# ESW3120 register map
Vendor: Shanghai Eastsoft Microelectronics Co.,Ltd.; Series: ARMCM3; File version: 1.2
CPU: CM3 r2p1, little endian, MPU, no FPU, 4 interrupt priority bits
Registers are 32-bit, read-write, reset 0x0 unless marked. A register's access mark holds for its fields unless they carry their own. Offsets are from the block's base; [hi:lo] are bit positions; {n}, {i} and the like mark numbered series.

## ADPCM
Base 0x40008800
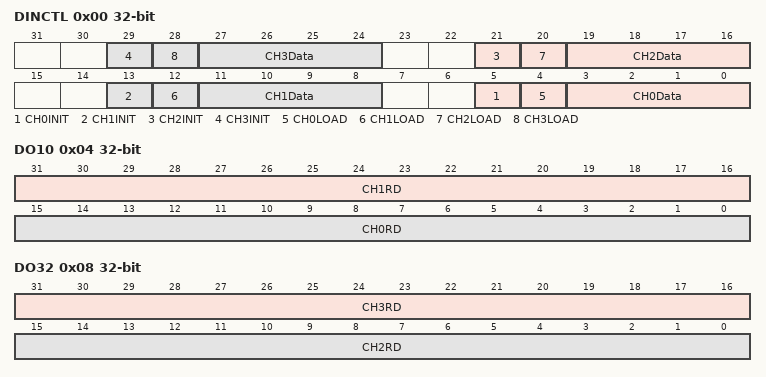
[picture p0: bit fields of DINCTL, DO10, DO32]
0x00 DINCTL
  [8n+5] CH{n}INIT (n=0..3), [8n+4] CH{n}LOAD (n=0..3), [8n+3:8n] CH{n}Data (n=0..3)
0x04 DO10 read
  [31:16] CH1RD, [15:0] CH0RD
0x08 DO32 read
  [31:16] CH3RD, [15:0] CH2RD
0x0C IER trigger-write1
  [0] IER
0x10 IDR trigger-write1
  [0] IDR
0x14 IMR read
  [0] IMR
0x18 RIS read
  [0] RIS
0x1C ISC write1
  [0] ISC read-clear-write1
0x20 STATUS read
  [0] DEC_READY
0x24 DMACTRL
  [0] DECDMAEN

## ADC
Base 0x40042000
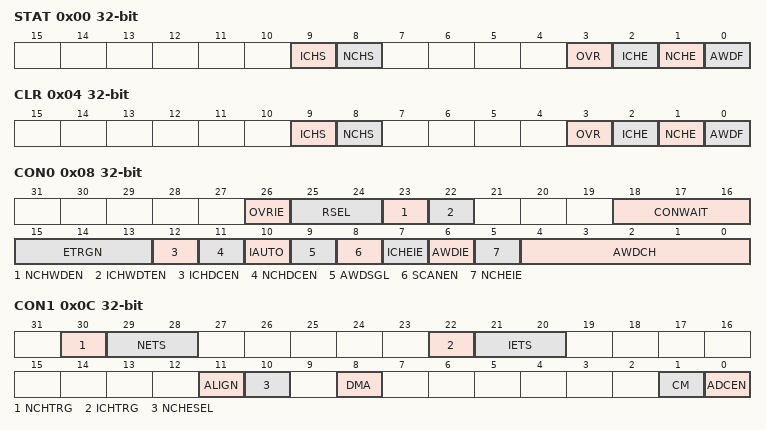
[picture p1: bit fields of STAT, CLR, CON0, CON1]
0x00 STAT read
  [9] ICHS, [8] NCHS, [3] OVR, [2] ICHE, [1] NCHE, [0] AWDF
0x04 CLR write1
  [9] ICHS, [8] NCHS, [3] OVR, [2] ICHE, [1] NCHE, [0] AWDF
0x08 CON0
  [26] OVRIE, [25:24] RSEL, [23] NCHWDEN, [22] ICHWDTEN, [18:16] CONWAIT, [15:13] ETRGN, [12] ICHDCEN, [11] NCHDCEN, [10] IAUTO, [9] AWDSGL, [8] SCANEN, [7] ICHEIE, [6] AWDIE, [5] NCHEIE, [4:0] AWDCH
0x0C CON1
  [30] NCHTRG write1, [29:28] NETS, [22] ICHTRG write1, [21:20] IETS, [11] ALIGN, [10] NCHESEL, [8] DMA, [1] CM, [0] ADCEN
0x10 SMPT1
  [31:0] CHT
0x14 SMPT2
  [31:0] CHT
0x18 SMPT3
  [31:0] SMP
{0x1C+4i} ICHOFF{i} (i=1..4)
  [11:0] IOFF{i}
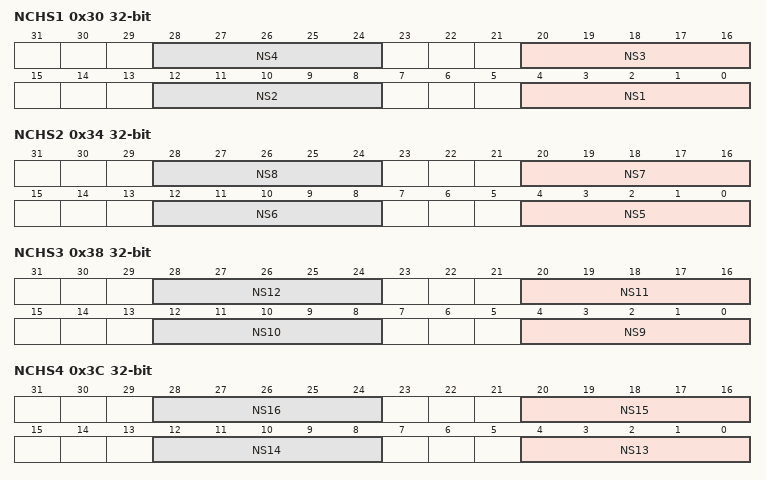
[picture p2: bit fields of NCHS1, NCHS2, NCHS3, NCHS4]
0x30 NCHS1
  [8n-4:8n-8] NS{n} (n=1..4)
0x34 NCHS2
  [8n-36:8n-40] NS{n} (n=5..8)
0x38 NCHS3
  [8n-68:8n-72] NS{n} (n=9..12)
0x3C NCHS4
  [8n-100:8n-104] NS{n} (n=13..16)
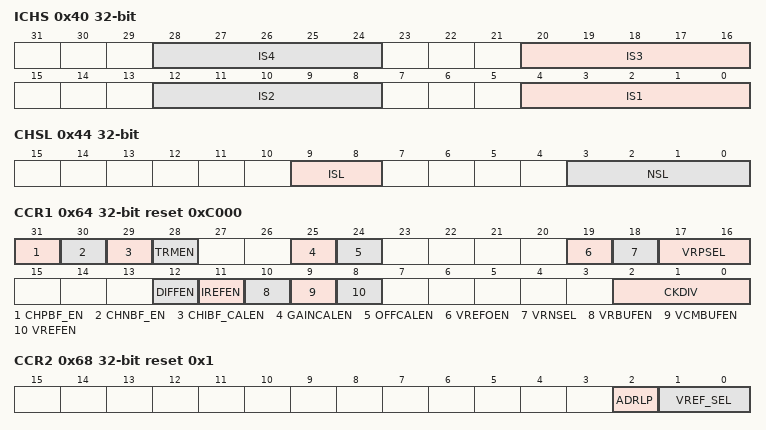
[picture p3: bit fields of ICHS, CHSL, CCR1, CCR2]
0x40 ICHS
  [8n-4:8n-8] IS{n} (n=1..4)
0x44 CHSL
  [9:8] ISL, [3:0] NSL
0x48 WDTH reset 0xFFF
  [11:0] HT
0x4C WDTL
  [11:0] LT
{0x4C+4i} ICHDR{i} read (i=1..4)
  [15:0] VAL
0x60 NCHDR read
  [15:0] VAL
0x64 CCR1 reset 0xC000
  [31] CHPBF_EN, [30] CHNBF_EN, [29] CHIBF_CALEN, [28] TRMEN, [25] GAINCALEN, [24] OFFCALEN, [19] VREFOEN, [18] VRNSEL, [17:16] VRPSEL, [12] DIFFEN, [11] IREFEN, [10] VRBUFEN, [9] VCMBUFEN, [8] VREFEN, [2:0] CKDIV
0x68 CCR2 reset 0x1
  [2] ADRLP, [1:0] VREF_SEL

## CFG
Base 0x40083C00
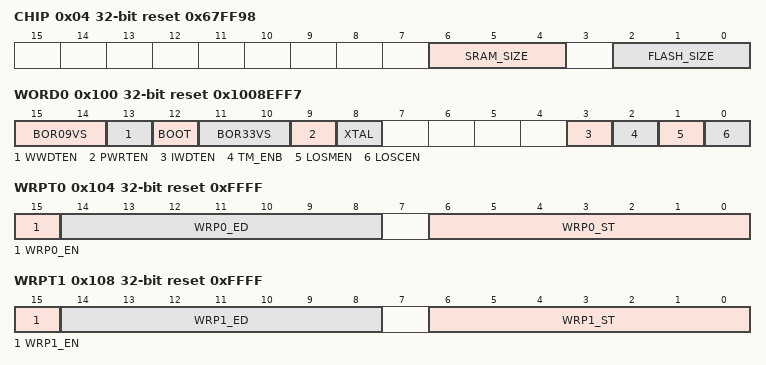
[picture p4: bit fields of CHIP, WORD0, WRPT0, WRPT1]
0x04 CHIP read reset 0x67FF98
  [6:4] SRAM_SIZE, [2:0] FLASH_SIZE
0x08 BOOT read
0x100 WORD0 read reset 0x1008EFF7
  [15:14] BOR09VS, [13] WWDTEN, [12] BOOT, [11:10] BOR33VS, [9] PWRTEN, [8] XTAL, [3] IWDTEN, [2] TM_ENB, [1] LOSMEN, [0] LOSCEN
0x104 WRPT0 read reset 0xFFFF
  [15] WRP0_EN, [14:8] WRP0_ED, [6:0] WRP0_ST
0x108 WRPT1 read reset 0xFFFF
  [15] WRP1_EN, [14:8] WRP1_ED, [6:0] WRP1_ST
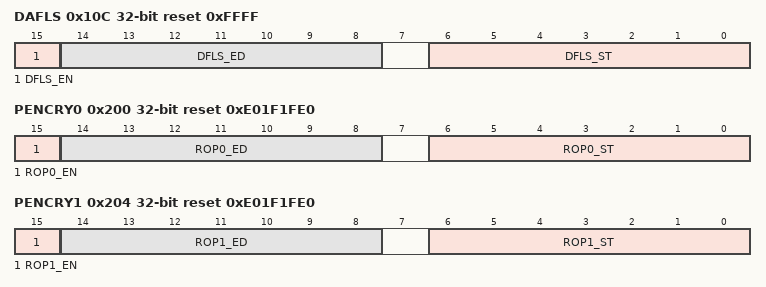
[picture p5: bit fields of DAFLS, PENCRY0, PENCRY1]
0x10C DAFLS read reset 0xFFFF
  [15] DFLS_EN, [14:8] DFLS_ED, [6:0] DFLS_ST
0x110 GBRDP read reset 0xFFFF
  [7:0] GDRDP
0x114 XTAL read reset 0x7FFF80
  [7:0] CAPCAL
0x200 PENCRY0 read reset 0xE01F1FE0
  [15] ROP0_EN, [14:8] ROP0_ED, [6:0] ROP0_ST
0x204 PENCRY1 read reset 0xE01F1FE0
  [15] ROP1_EN, [14:8] ROP1_ED, [6:0] ROP1_ST

## CALC
Base 0x40085400
0x00 SQRTSR read
  [0] BUSY
0x04 RDCND
  [31:0] RADICAND
0x08 SQRTRES read
  [15:0] RESULT
0x20 DIVDR
  [31:0] DIVD
0x24 DIVSR
  [31:0] DIVS
0x28 DIVQR read
  [31:0] DIVQ
0x2C DIVRR read
  [31:0] DIVS
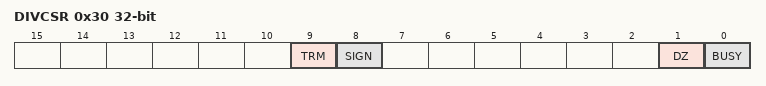
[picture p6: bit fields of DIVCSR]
0x30 DIVCSR read
  [9] TRM rw, [8] SIGN rw, [1] DZ, [0] BUSY

## BKPC
Base 0x40049000
0x00 PROT read reset 0x1
  [31:0] KEY write, [0] PROT
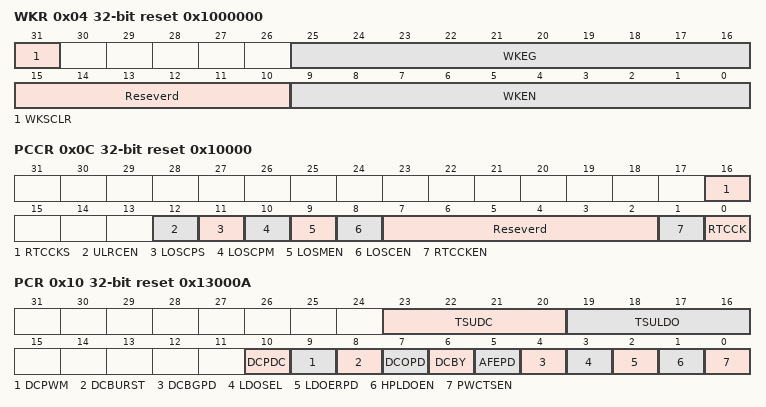
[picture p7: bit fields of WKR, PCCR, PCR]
0x04 WKR reset 0x1000000
  [31] WKSCLR write1, [25:16] WKEG, [15:10] Reseverd none, [9:0] WKEN
0x08 WKSR read
  [9:0] WKF
0x0C PCCR reset 0x10000
  [16] RTCCKS read, [12] ULRCEN, [11] LOSCPS, [10] LOSCPM, [9] LOSMEN, [8] LOSCEN, [7:2] Reseverd none, [1] RTCCKEN, [0] RTCCK
0x10 PCR reset 0x13000A
  [23:20] TSUDC, [19:16] TSULDO, [10] DCPDC, [9] DCPWM, [8] DCBURST, [7] DCOPD, [6] DCBY, [5] AFEPD, [4] DCBGPD, [3] LDOSEL, [2] LDOERPD, [1] HPLDOEN, [0] PWCTSEN

## HASH
Base 0x40086800
0x00 DIN write
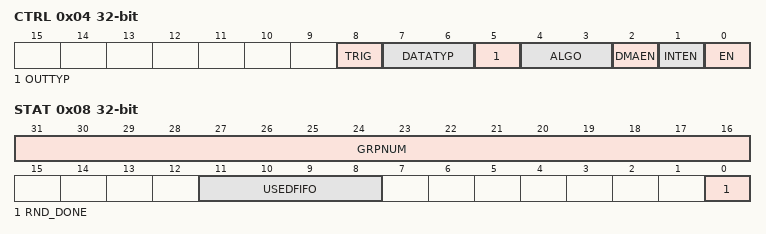
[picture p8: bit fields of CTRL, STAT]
0x04 CTRL
  [8] TRIG, [7:6] DATATYP, [5] OUTTYP, [4:3] ALGO, [2] DMAEN, [1] INTEN, [0] EN
0x08 STAT
  [31:16] GRPNUM read, [11:8] USEDFIFO read, [0] RND_DONE
{0xC+4i} RES{i} read (i=0..7)
